VERSION "CANopener test"

NS_ :

BS_:

BU_: ECU1 TOOL

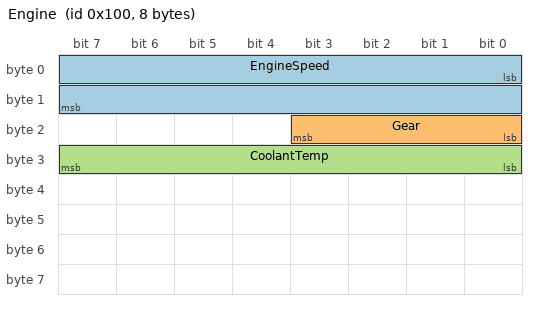
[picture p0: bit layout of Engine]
BO_ 256 Engine: 8 ECU1
 SG_ EngineSpeed : 0|16@1+ (0.25,0) [0|16383.75] "rpm" TOOL
 SG_ Gear : 16|4@1+ (1,0) [0|15] "" TOOL
 SG_ CoolantTemp : 24|8@1+ (1,-40) [-40|215] "degC" TOOL

BO_ 512 MuxMsg: 8 ECU1
 SG_ Selector M : 0|8@1+ (1,0) [0|255] "" TOOL
 SG_ ValueA m0 : 8|16@1+ (1,0) [0|65535] "" TOOL
 SG_ ValueB m1 : 8|16@1- (0.5,0) [-16384|16383.5] "V" TOOL

BO_ 2364539904 EEC1: 8 ECU1
 SG_ EngineTorqueMode : 0|4@1+ (1,0) [0|15] "" TOOL
 SG_ EngineSpeed : 24|16@1+ (0.125,0) [0|8031.875] "rpm" TOOL

BO_ 2566848513 PropLong: 16 ECU1
 SG_ Value1 : 0|16@1+ (1,0) [0|65535] "" TOOL
 SG_ Value2 : 96|32@1+ (1,0) [0|4294967295] "" TOOL

BA_DEF_ BO_ "VFrameFormat" ENUM "StandardCAN","ExtendedCAN","reserved","J1939PG";
BA_DEF_DEF_ "VFrameFormat" "StandardCAN";
BA_ "VFrameFormat" BO_ 2364539904 3;
BA_ "VFrameFormat" BO_ 2566848513 3;

VAL_ 256 Gear 0 "Neutral" 1 "First" 2 "Second" 15 "Reverse" ;
